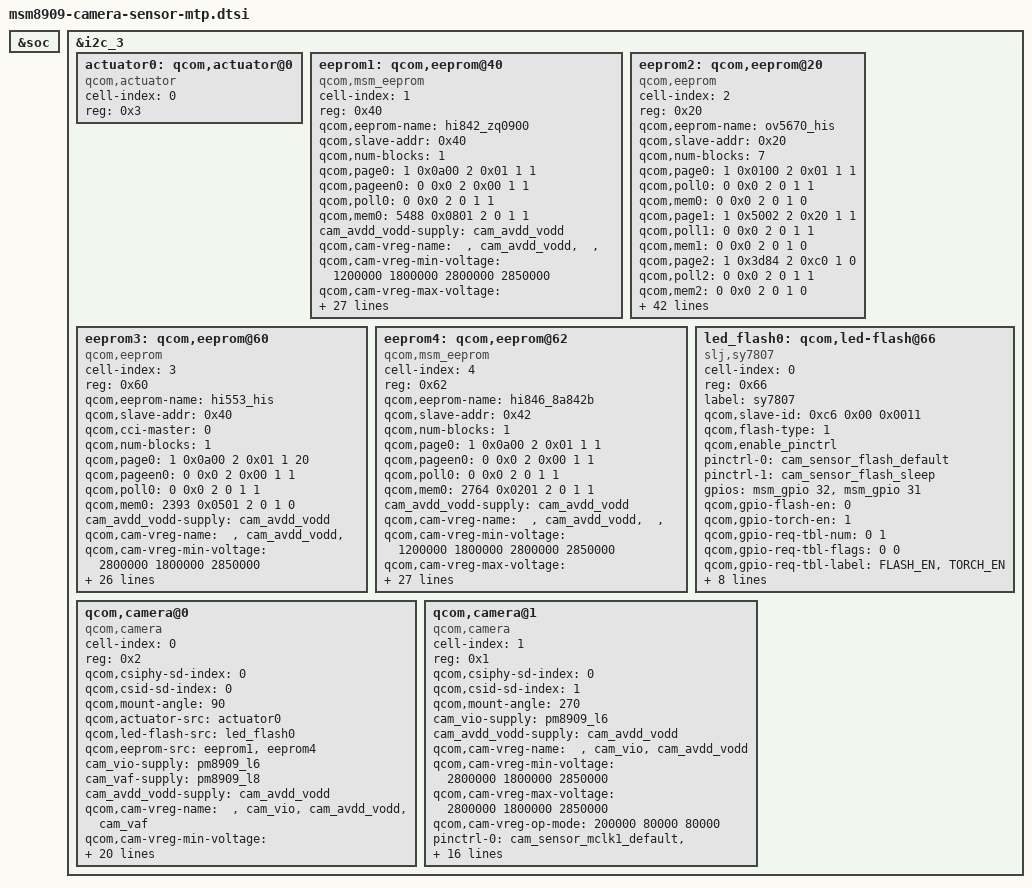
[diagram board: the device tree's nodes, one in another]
/*
 * Copyright (c) 2014, The Linux Foundation. All rights reserved.
 *
 * This program is free software; you can redistribute it and/or modify
 * it under the terms of the GNU General Public License version 2 and
 * only version 2 as published by the Free Software Foundation.
 *
 * This program is distributed in the hope that it will be useful,
 * but WITHOUT ANY WARRANTY; without even the implied warranty of
 * MERCHANTABILITY or FITNESS FOR A PARTICULAR PURPOSE.  See the
 * GNU General Public License for more details.
 */

&soc {

	
};

&i2c_3 {

	actuator0: qcom,actuator@0 {
		cell-index = <0>;
		reg = <0x3>;
		compatible = "qcom,actuator";
	};

  eeprom1: qcom,eeprom@40{
		cell-index = <1>;
		reg = <0x40>;
		qcom,eeprom-name = "hi842_zq0900";
		compatible = "qcom,msm_eeprom";
		qcom,slave-addr = <0x40>;
		qcom,num-blocks = <1>;
		
		
		
		qcom,page0 = <1 0x0a00 2 0x01 1 1>;
		qcom,pageen0 = <0 0x0 2 0x00 1 1>;
		qcom,poll0 = <0 0x0 2 0 1 1>;
		qcom,mem0 = <5488 0x0801 2 0 1 1>;
		
		
		cam_avdd_vodd-supply = <&cam_avdd_vodd>;///jp added		
		qcom,cam-vreg-name = " ", "cam_avdd_vodd", " "," "; 
		qcom,cam-vreg-min-voltage = <1200000 1800000 2800000 2850000>;//  jp  invalid
		qcom,cam-vreg-max-voltage = <1200000 1800000 2850000 2900000>;// jp in valid
		qcom,cam-vreg-op-mode = <200000 80000 80000 100000>;
		qcom,enable_pinctrl;
		pinctrl-names = "cam_default", "cam_suspend";
		pinctrl-0 = <&cam_sensor_mclk0_default
					&cam_sensor_rear_default>;
		pinctrl-1 = <&cam_sensor_mclk0_sleep &cam_sensor_rear_sleep>;
		gpios = <&msm_gpio 26 0>,
			<&msm_gpio 35 0>,
			<&msm_gpio 34 0>;
		qcom,gpio-reset = <1>;
		qcom,gpio-standby = <2>;
		qcom,gpio-req-tbl-num = <0 1 2>;
		qcom,gpio-req-tbl-flags = <1 0 0>;
		qcom,gpio-req-tbl-label = "CAM0_MCLK",
						"CAM0_RESET",
						"CAM0_STANDBY";
		qcom,cam-power-seq-type = "sensor_gpio","sensor_gpio","sensor_vreg","sensor_clk","sensor_gpio","sensor_gpio" ,"sensor_i2c_mux";
		qcom,cam-power-seq-val = "sensor_gpio_standby","sensor_gpio_reset","cam_avdd_vodd","sensor_cam_mclk","sensor_gpio_standby","sensor_gpio_reset","none";
		qcom,cam-power-seq-cfg-val = <0 0 1 24000000 1 1 0>;
		qcom,cam-power-seq-delay = <1 1 5 10 5 10 0>;
		clocks = <&clock_gcc clk_mclk0_clk_src>,
			<&clock_gcc clk_gcc_camss_mclk0_clk>;
		clock-names = "cam_src_clk", "cam_clk";
	};
	
	eeprom2: qcom,eeprom@20{
		cell-index = <2>;
		reg = <0x20>;
		qcom,eeprom-name = "ov5670_his";
		compatible = "qcom,eeprom";
		qcom,slave-addr = <0x20>;
		qcom,num-blocks = <7>;
		
		qcom,page0 = <1 0x0100 2 0x01 1 1>;
		qcom,poll0 = <0 0x0 2 0 1 1>;
		qcom,mem0 = <0 0x0 2 0 1 0>;
		
		qcom,page1 = <1 0x5002 2 0x20 1 1>;
		qcom,poll1 = <0 0x0 2 0 1 1>;
		qcom,mem1 = <0 0x0 2 0 1 0>;
		
		qcom,page2 = <1 0x3d84 2 0xc0 1 0>;
		qcom,poll2 = <0 0x0 2 0 1 1>;
		qcom,mem2 = <0 0x0 2 0 1 0>;
		
		qcom,page3 = <1 0x3d88 2 0x7010 2 0>;
		qcom,poll3 = <0 0x0 2 0 1 1>;
		qcom,mem3 = <0 0x0 2 0 1 0>;
		
		qcom,page4 = <1 0x3d8a 2 0x7029 2 0>;
		qcom,poll4 = <0 0x0 2 0 1 1>;
		qcom,mem4 = <0 0x0 2 0 1 0>;
		
		qcom,page5 = <1 0x3d81 2 0x01 1 15>;
		qcom,poll5 = <0 0x0 2 0 1 1>;
		qcom,mem5 = <26 0x7010 2 0 1 0>;
		
		qcom,page6 = <1 0x5002 2 0x28 1 1>;
		qcom,poll6 = <0 0x0 2 0 1 1>;
		qcom,mem6 = <0 0x0 2 0 1 0>;

    cam_avdd_vodd-supply = <&cam_avdd_vodd>;
		qcom,cam-vreg-name = " ", "cam_avdd_vodd", " ";
		qcom,cam-vreg-min-voltage = <2800000 1800000 2850000 >;
		qcom,cam-vreg-max-voltage = <2800000 1800000 2850000 >;
		qcom,cam-vreg-op-mode = <200000 80000 80000 >;  
		pinctrl-names = "cam_default", "cam_suspend";
		pinctrl-0 = <&cam_sensor_mclk1_default &cam_sensor_front_default>;
		pinctrl-1 = <&cam_sensor_mclk1_sleep &cam_sensor_front_sleep>;
		gpios = <&msm_gpio 27 0>,
			<&msm_gpio 28 0>,
			<&msm_gpio 33 0>;
		qcom,gpio-reset = <1>;
		qcom,gpio-standby = <2>;
		qcom,gpio-req-tbl-num = <0 1 2>;
		qcom,gpio-req-tbl-flags = <1 0 0>;
		qcom,gpio-req-tbl-label = "CAM1_MCLK",
			"CAM1_RESET",
			"CAM1_STANDBY";
		qcom,cam-power-seq-type = "sensor_gpio","sensor_gpio","sensor_vreg",
					"sensor_gpio","sensor_gpio", "sensor_clk","sensor_i2c_mux";
		qcom,cam-power-seq-val = "sensor_gpio_reset","sensor_gpio_standby",
					"cam_avdd_vodd","sensor_gpio_reset","sensor_gpio_standby",
					"sensor_cam_mclk", "none";
		qcom,cam-power-seq-cfg-val = <0 0 1 1 1 24000000 0>;
		qcom,cam-power-seq-delay = <1 1  1 1 1 5 0>;
		clocks = <&clock_gcc clk_mclk1_clk_src>,
				 <&clock_gcc clk_gcc_camss_mclk1_clk>;
		clock-names = "cam_src_clk", "cam_clk";
	};
	
	eeprom3: qcom,eeprom@60{
		cell-index = <3>;
		reg = <0x60>;
		qcom,eeprom-name = "hi553_his";
		compatible = "qcom,eeprom";
		qcom,slave-addr = <0x40>;
	    qcom,cci-master = <0>;
	    qcom,num-blocks = <1>;

	    qcom,page0 = <1 0x0a00 2 0x01 1 20>;
	    qcom,pageen0 = <0 0x0 2 0x00 1 1>;
	    qcom,poll0 = <0 0x0 2 0 1 1>;
	    qcom,mem0 = <2393 0x0501 2 0 1 0>;

        cam_avdd_vodd-supply = <&cam_avdd_vodd>;
	    qcom,cam-vreg-name = " ", "cam_avdd_vodd", " ";
		qcom,cam-vreg-min-voltage = <2800000 1800000 2850000 >;
		qcom,cam-vreg-max-voltage = <2800000 1800000 2850000 >;
		qcom,cam-vreg-op-mode = <200000 80000 80000 >;  
		pinctrl-names = "cam_default", "cam_suspend";
		pinctrl-0 = <&cam_sensor_mclk1_default &cam_sensor_front_default>;
		pinctrl-1 = <&cam_sensor_mclk1_sleep &cam_sensor_front_sleep>;
		gpios = <&msm_gpio 27 0>,
			<&msm_gpio 28 0>,
			<&msm_gpio 33 0>;
		qcom,gpio-reset = <1>;
		qcom,gpio-standby = <2>;
		qcom,gpio-req-tbl-num = <0 1 2>;
		qcom,gpio-req-tbl-flags = <1 0 0>;
		qcom,gpio-req-tbl-label = "CAM1_MCLK",
			"CAM1_RESET",
			"CAM1_STANDBY";
		qcom,cam-power-seq-type = "sensor_gpio","sensor_gpio","sensor_vreg",
					"sensor_gpio","sensor_gpio", "sensor_clk","sensor_i2c_mux";
		qcom,cam-power-seq-val = "sensor_gpio_reset","sensor_gpio_standby",
					"cam_avdd_vodd","sensor_gpio_reset","sensor_gpio_standby",
					"sensor_cam_mclk", "none";
		qcom,cam-power-seq-cfg-val = <0 0 1 1 1 24000000 0>;
		qcom,cam-power-seq-delay = <1 1  1 1 1 5 0>;
		clocks = <&clock_gcc clk_mclk1_clk_src>,
				 <&clock_gcc clk_gcc_camss_mclk1_clk>;
		clock-names = "cam_src_clk", "cam_clk";
	};

  eeprom4: qcom,eeprom@62{
		cell-index = <4>;
		reg = <0x62>;
		qcom,eeprom-name = "hi846_8a842b";
		compatible = "qcom,msm_eeprom";
		qcom,slave-addr = <0x42>;
		qcom,num-blocks = <1>;

		qcom,page0 = <1 0x0a00 2 0x01 1 1>;
		qcom,pageen0 = <0 0x0 2 0x00 1 1>;
		qcom,poll0 = <0 0x0 2 0 1 1>;
		qcom,mem0 = <2764 0x0201 2 0 1 1>;

		cam_avdd_vodd-supply = <&cam_avdd_vodd>;///jp added
		qcom,cam-vreg-name = " ", "cam_avdd_vodd", " "," ";
		qcom,cam-vreg-min-voltage = <1200000 1800000 2800000 2850000>;//  jp  invalid
		qcom,cam-vreg-max-voltage = <1200000 1800000 2850000 2900000>;// jp in valid
		qcom,cam-vreg-op-mode = <200000 80000 80000 100000>;
		qcom,enable_pinctrl;
		pinctrl-names = "cam_default", "cam_suspend";
		pinctrl-0 = <&cam_sensor_mclk0_default
					&cam_sensor_rear_default>;
		pinctrl-1 = <&cam_sensor_mclk0_sleep &cam_sensor_rear_sleep>;
		gpios = <&msm_gpio 26 0>,
			<&msm_gpio 35 0>,
			<&msm_gpio 34 0>;
		qcom,gpio-reset = <1>;
		qcom,gpio-standby = <2>;
		qcom,gpio-req-tbl-num = <0 1 2>;
		qcom,gpio-req-tbl-flags = <1 0 0>;
		qcom,gpio-req-tbl-label = "CAM0_MCLK",
						"CAM0_RESET",
						"CAM0_STANDBY";
		qcom,cam-power-seq-type = "sensor_gpio","sensor_gpio","sensor_vreg","sensor_clk","sensor_gpio","sensor_gpio" ,"sensor_i2c_mux";
		qcom,cam-power-seq-val = "sensor_gpio_standby","sensor_gpio_reset","cam_avdd_vodd","sensor_cam_mclk","sensor_gpio_standby","sensor_gpio_reset","none";
		qcom,cam-power-seq-cfg-val = <0 0 1 24000000 1 1 0>;
		qcom,cam-power-seq-delay = <1 1 5 10 5 10 0>;
		clocks = <&clock_gcc clk_mclk0_clk_src>,
			<&clock_gcc clk_gcc_camss_mclk0_clk>;
		clock-names = "cam_src_clk", "cam_clk";
	};

	led_flash0: qcom,led-flash@66 {
		cell-index = <0>;
		reg = <0x66>;
		compatible = "slj,sy7807";
		label = "sy7807";
		qcom,slave-id = <0xc6 0x00 0x0011>;
		qcom,flash-type = <1>;		
		qcom,enable_pinctrl;		
		pinctrl-names = "cam_flash_default", "cam_flash_suspend";
		pinctrl-0 = <&cam_sensor_flash_default>;
		pinctrl-1 = <&cam_sensor_flash_sleep>;
		gpios = <&msm_gpio 32 0>,
					  <&msm_gpio 31 0>;
		qcom,gpio-flash-en = <0>;
		qcom,gpio-torch-en = <1>;
		qcom,gpio-req-tbl-num = <0 1>;
		qcom,gpio-req-tbl-flags = <0 0>;
		qcom,gpio-req-tbl-label = "FLASH_EN", "TORCH_EN";
		
		qcom,flash-max-current = <1500>;
		qcom,flash-op-current = <1000>;
		qcom,torch-max-current = <300>;
		qcom,torch-op-current = <290>;
		
		clocks = <&clock_gcc clk_camss_gp0_clk_src>,
		         <&clock_gcc clk_gcc_camss_gp0_clk>,
		         <&clock_gcc clk_camss_gp1_clk_src>,
		         <&clock_gcc clk_gcc_camss_gp1_clk>;
		clock-names = "torch_src_clk",
									"torch_clk",
									"flash_src_clk",
									"flash_clk";
	};
	
	qcom,camera@0{
		cell-index = <0>;
		compatible = "qcom,camera";
		reg = <0x2>;// jp don't change it. it used for probe. if we changed it to 0. the driver don't probe.
		qcom,csiphy-sd-index = <0>;
		qcom,csid-sd-index = <0>;
		qcom,mount-angle = <90>;
		qcom,actuator-src = <&actuator0>;
		qcom,led-flash-src = <&led_flash0>;
		qcom,eeprom-src = <&eeprom1 &eeprom4>;
		cam_vio-supply = <&pm8909_l6>;
		cam_vaf-supply = <&pm8909_l8>;
		cam_avdd_vodd-supply = <&cam_avdd_vodd>;
		qcom,cam-vreg-name = " ", "cam_vio", "cam_avdd_vodd",	"cam_vaf";
		qcom,cam-vreg-min-voltage = <1200000 1800000 2800000 2850000>;
		qcom,cam-vreg-max-voltage = <1200000 1800000 2850000 2900000>;
		qcom,cam-vreg-op-mode = <200000 80000 80000 100000>;
		pinctrl-names = "cam_default", "cam_suspend";
		pinctrl-0 = <&cam_sensor_mclk0_default
				&cam_sensor_rear_default>;
		pinctrl-1 = <&cam_sensor_mclk0_sleep &cam_sensor_rear_sleep>;
		gpios = <&msm_gpio 26 0>,
			<&msm_gpio 35 0>,
			<&msm_gpio 34 0>;
		qcom,gpio-reset = <1>;
		qcom,gpio-standby = <2>;
		qcom,gpio-req-tbl-num = <0 1 2>;
		qcom,gpio-req-tbl-flags = <1 0 0>;
		qcom,gpio-req-tbl-label = "CAM0_MCLK",
			"CAM0_RESET",
			"CAM0_STANDBY";
		qcom,sensor-position = <0>;
		qcom,sensor-mode = <0>;
		status = "ok";
		clocks = <&clock_gcc clk_mclk0_clk_src>,
				<&clock_gcc clk_gcc_camss_mclk0_clk>;
		clock-names = "cam_src_clk", "cam_clk";
	};

	qcom,camera@1 {
		cell-index = <1>;
		compatible = "qcom,camera";
		reg = <0x1>;
		qcom,csiphy-sd-index = <0>;// jp it must be 0. because the 8909 platform have only one CSIPHY
		qcom,csid-sd-index = <1>; 
		qcom,mount-angle = <270>;
		//qcom,eeprom-src = <&eeprom2 &eeprom3>;
		cam_vio-supply = <&pm8909_l6>;
		cam_avdd_vodd-supply = <&cam_avdd_vodd>;
		qcom,cam-vreg-name = " ", "cam_vio", "cam_avdd_vodd";
		qcom,cam-vreg-min-voltage = <2800000 1800000 2850000 >;
		qcom,cam-vreg-max-voltage = <2800000 1800000 2850000 >;
		qcom,cam-vreg-op-mode = <200000 80000 80000 >;  
		pinctrl-names = "cam_default", "cam_suspend";
		pinctrl-0 = <&cam_sensor_mclk1_default &cam_sensor_front_default &cam_sensor_front_default1>;
		pinctrl-1 = <&cam_sensor_mclk1_sleep &cam_sensor_front_sleep  &cam_sensor_front_sleep1>;
		gpios = <&msm_gpio 27 0>,
			<&msm_gpio 28 0>,
			<&msm_gpio 33 0>;
		qcom,gpio-reset = <1>;
		qcom,gpio-standby = <2>;
		qcom,gpio-req-tbl-num = <0 1 2>;
		qcom,gpio-req-tbl-flags = <1 0 0>;
		qcom,gpio-req-tbl-label = "CAM1_MCLK",
			"CAM1_RESET",
			"CAM1_STANDBY";
		qcom,sensor-position = <1>;
		qcom,sensor-mode = <0>;			
		status = "ok";
		clocks = <&clock_gcc clk_mclk1_clk_src>,
				<&clock_gcc clk_gcc_camss_mclk1_clk>;
		clock-names = "cam_src_clk", "cam_clk";
	};
};
